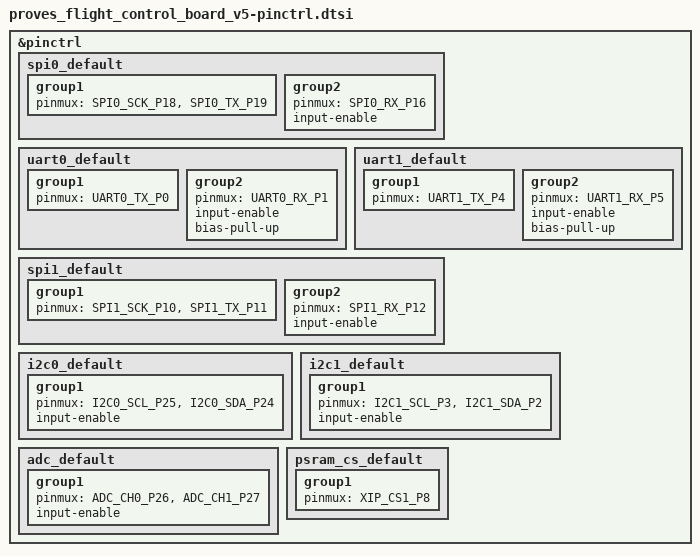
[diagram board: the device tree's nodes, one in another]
#include <zephyr/dt-bindings/pinctrl/rpi-pico-rp2350a-pinctrl.h>
#include "proves_flight_control_board_v5-qspi-pinctrl.h"

&pinctrl {
	spi0_default: spi0_default {
		group1 {
			pinmux = <SPI0_SCK_P18>, <SPI0_TX_P19>;
		};

		group2 {
			pinmux = <SPI0_RX_P16>;
			input-enable;
		};
	};
	uart0_default: uart0_default {
		group1 {
			pinmux = <UART0_TX_P0>;
		};

		group2 {
			pinmux = <UART0_RX_P1>;
			input-enable;
			bias-pull-up;
		};
	};
	uart1_default: uart1_default {
		group1 {
			pinmux = <UART1_TX_P4>;
		};

		group2 {
			pinmux = <UART1_RX_P5>;
			input-enable;
			bias-pull-up;
		};
	};
	spi1_default: spi1_default {
		group1 {
			pinmux = <SPI1_SCK_P10>, <SPI1_TX_P11>;
		};

		group2 {
			pinmux = <SPI1_RX_P12>;
			input-enable;
		};
	};
	i2c0_default: i2c0_default {
		group1 {
			pinmux = <I2C0_SCL_P25>, <I2C0_SDA_P24>;
			input-enable;
		};
	};
	i2c1_default: i2c1_default {
		group1 {
			pinmux = <I2C1_SCL_P3>, <I2C1_SDA_P2>;
			input-enable;
		};
	};
	adc_default: adc_default {
		group1 {
			pinmux = <ADC_CH0_P26>,		/* GP26: ADC_CH0 */
					<ADC_CH1_P27>;		/* GP27: ADC_CH1 */
			input-enable;
		};
	};
	/* GPIO8 -> XIP_CS1n (alt function 9): PSRAM chip select on QMI CS1 */
	psram_cs_default: psram_cs_default {
		group1 {
			pinmux = <XIP_CS1_P8>;
		};
	};
};
